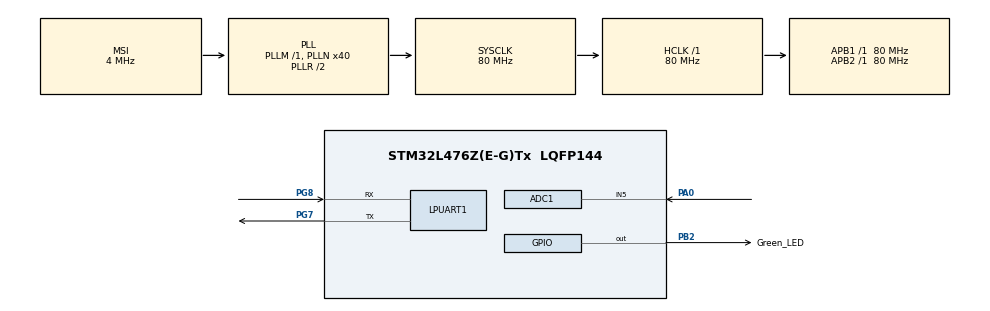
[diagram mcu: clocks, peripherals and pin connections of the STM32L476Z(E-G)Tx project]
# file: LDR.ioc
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ADC1.Channel-1\#ChannelRegularConversion=ADC_CHANNEL_5
ADC1.EnableRegularConversion=ENABLE
ADC1.NbrOfConversionFlag=1
ADC1.OffsetNumber-1\#ChannelRegularConversion=ADC_OFFSET_NONE
ADC1.Rank-1\#ChannelRegularConversion=1
ADC1.SamplingTime-1\#ChannelRegularConversion=ADC_SAMPLETIME_2CYCLES_5
ADC1.master=1
LPUART1.WordLength=UART_WORDLENGTH_8B
Mcu.Family=STM32L4
Mcu.Name=STM32L476Z(E-G)Tx
Mcu.Package=LQFP144
NVIC.PriorityGroup=NVIC_PRIORITYGROUP_4
PA0.Signal=ADCx_IN5
PA13\ (JTMS-SWDIO).Mode=Serial_Wire
PA13\ (JTMS-SWDIO).Signal=SYS_JTMS-SWDIO
PA14\ (JTCK-SWCLK).Mode=Serial_Wire
PA14\ (JTCK-SWCLK).Signal=SYS_JTCK-SWCLK
PB2.GPIO_Label=Green_LED
PB2.Signal=GPIO_Output
PG7.Mode=Asynchronous
PG7.Signal=LPUART1_TX
PG8.Mode=Asynchronous
PG8.Signal=LPUART1_RX
PH0-OSC_IN\ (PH0).Mode=HSE-External-Oscillator
PH0-OSC_IN\ (PH0).Signal=RCC_OSC_IN
PH1-OSC_OUT\ (PH1).Mode=HSE-External-Oscillator
PH1-OSC_OUT\ (PH1).Signal=RCC_OSC_OUT
ProjectManager.HeapSize=0x200
ProjectManager.StackSize=0x400
ProjectManager.TargetToolchain=STM32CubeIDE
RCC.ADCFreq_Value=32000000
RCC.AHBFreq_Value=80000000
RCC.APB1Freq_Value=80000000
RCC.APB1TimFreq_Value=80000000
RCC.APB2Freq_Value=80000000
RCC.APB2TimFreq_Value=80000000
RCC.CortexFreq_Value=80000000
RCC.HCLKFreq_Value=80000000
RCC.HSE_VALUE=8000000
RCC.HSI_VALUE=16000000
RCC.LSE_VALUE=32768
RCC.MSI_VALUE=4000000
RCC.PLLN=40
RCC.PLLSAI1N=16
RCC.SYSCLKFreq_VALUE=80000000
RCC.SYSCLKSource=RCC_SYSCLKSOURCE_PLLCLK
RCC.USBFreq_Value=32000000
RCC.VCOOutputFreq_Value=160000000
SH.ADCx_IN5.0=ADC1_IN5,IN5-Single-Ended
board=custom

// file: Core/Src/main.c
/* USER CODE BEGIN Header */
/**
  ******************************************************************************
  * @file           : main.c
  * @brief          : Main program body
  ******************************************************************************
  * @attention
  *
  * Copyright (c) 2024 STMicroelectronics.
  * All rights reserved.
  *
  * This software is licensed under terms that can be found in the LICENSE file
  * in the root directory of this software component.
  * If no LICENSE file comes with this software, it is provided AS-IS.
  *
  ******************************************************************************
  */
/* USER CODE END Header */
#include "main.h"

/* USER CODE BEGIN Includes */
#include <stdio.h>
#include <string.h>

/* USER CODE END Includes */

ADC_HandleTypeDef hadc1;

UART_HandleTypeDef hlpuart1;

void SystemClock_Config(void);
static void MX_GPIO_Init(void);
static void MX_ADC1_Init(void);
static void MX_LPUART1_UART_Init(void);

/* USER CODE BEGIN 0 */
uint16_t data;
char buffer[20];

/* USER CODE END 0 */

int main(void)
{

  /* MCU Configuration--------------------------------------------------------*/

  /* Reset of all peripherals, Initializes the Flash interface and the Systick. */
  HAL_Init();

  /* Configure the system clock */
  SystemClock_Config();

  /* Initialize all configured peripherals */
  MX_GPIO_Init();
  MX_ADC1_Init();
  MX_LPUART1_UART_Init();

  /* Infinite loop */
  /* USER CODE BEGIN WHILE */
  while (1)
  {
	  HAL_ADC_Start(&hadc1);
	  HAL_ADC_PollForConversion(&hadc1, 20);
	  data = HAL_ADC_GetValue(&hadc1);
	  sprintf(buffer, "Value: %u \r \n", data);
	  HAL_UART_Transmit(&hlpuart1, (uint8_t *) buffer, strlen(buffer), HAL_MAX_DELAY);
	  HAL_Delay(500);

	  if (data > 1000)
	  {
		  HAL_GPIO_WritePin(GPIOB, GPIO_PIN_2, GPIO_PIN_SET);
	  }else
	  {
		  HAL_GPIO_WritePin(GPIOB, GPIO_PIN_2, GPIO_PIN_RESET);
	  }
	 // HAL_Delay(200);
//
//	  if((HAL_GPIO_ReadPin(GPIOA, GPIO_PIN_0) == GPIO_PIN_RESET))
//	{
//			  HAL_GPIO_WritePin(GPIOB, GPIO_PIN_2, GPIO_PIN_SET);
//  }else
//	  HAL_GPIO_WritePin(GPIOB, GPIO_PIN_2, GPIO_PIN_RESET);

    /* USER CODE END WHILE */

  }
}

void SystemClock_Config(void)
{
  RCC_OscInitTypeDef RCC_OscInitStruct = {0};
  RCC_ClkInitTypeDef RCC_ClkInitStruct = {0};

  /** Configure the main internal regulator output voltage
  */
  if (HAL_PWREx_ControlVoltageScaling(PWR_REGULATOR_VOLTAGE_SCALE1) != HAL_OK)
  {
    Error_Handler();
  }

  /** Initializes the RCC Oscillators according to the specified parameters
  * in the RCC_OscInitTypeDef structure.
  */
  RCC_OscInitStruct.OscillatorType = RCC_OSCILLATORTYPE_MSI;
  RCC_OscInitStruct.MSIState = RCC_MSI_ON;
  RCC_OscInitStruct.MSICalibrationValue = 0;
  RCC_OscInitStruct.MSIClockRange = RCC_MSIRANGE_6;
  RCC_OscInitStruct.PLL.PLLState = RCC_PLL_ON;
  RCC_OscInitStruct.PLL.PLLSource = RCC_PLLSOURCE_MSI;
  RCC_OscInitStruct.PLL.PLLM = 1;
  RCC_OscInitStruct.PLL.PLLN = 40;
  RCC_OscInitStruct.PLL.PLLP = RCC_PLLP_DIV7;
  RCC_OscInitStruct.PLL.PLLQ = RCC_PLLQ_DIV2;
  RCC_OscInitStruct.PLL.PLLR = RCC_PLLR_DIV2;
  if (HAL_RCC_OscConfig(&RCC_OscInitStruct) != HAL_OK)
  {
    Error_Handler();
  }

  /** Initializes the CPU, AHB and APB buses clocks
  */
  RCC_ClkInitStruct.ClockType = RCC_CLOCKTYPE_HCLK|RCC_CLOCKTYPE_SYSCLK
                              |RCC_CLOCKTYPE_PCLK1|RCC_CLOCKTYPE_PCLK2;
  RCC_ClkInitStruct.SYSCLKSource = RCC_SYSCLKSOURCE_PLLCLK;
  RCC_ClkInitStruct.AHBCLKDivider = RCC_SYSCLK_DIV1;
  RCC_ClkInitStruct.APB1CLKDivider = RCC_HCLK_DIV1;
  RCC_ClkInitStruct.APB2CLKDivider = RCC_HCLK_DIV1;

  if (HAL_RCC_ClockConfig(&RCC_ClkInitStruct, FLASH_LATENCY_4) != HAL_OK)
  {
    Error_Handler();
  }
}

static void MX_ADC1_Init(void)
{

  ADC_MultiModeTypeDef multimode = {0};
  ADC_ChannelConfTypeDef sConfig = {0};

  /** Common config
  */
  hadc1.Instance = ADC1;
  hadc1.Init.ClockPrescaler = ADC_CLOCK_ASYNC_DIV1;
  hadc1.Init.Resolution = ADC_RESOLUTION_12B;
  hadc1.Init.DataAlign = ADC_DATAALIGN_RIGHT;
  hadc1.Init.ScanConvMode = ADC_SCAN_DISABLE;
  hadc1.Init.EOCSelection = ADC_EOC_SINGLE_CONV;
  hadc1.Init.LowPowerAutoWait = DISABLE;
  hadc1.Init.ContinuousConvMode = DISABLE;
  hadc1.Init.NbrOfConversion = 1;
  hadc1.Init.DiscontinuousConvMode = DISABLE;
  hadc1.Init.ExternalTrigConv = ADC_SOFTWARE_START;
  hadc1.Init.ExternalTrigConvEdge = ADC_EXTERNALTRIGCONVEDGE_NONE;
  hadc1.Init.DMAContinuousRequests = DISABLE;
  hadc1.Init.Overrun = ADC_OVR_DATA_PRESERVED;
  hadc1.Init.OversamplingMode = DISABLE;
  if (HAL_ADC_Init(&hadc1) != HAL_OK)
  {
    Error_Handler();
  }

  /** Configure the ADC multi-mode
  */
  multimode.Mode = ADC_MODE_INDEPENDENT;
  if (HAL_ADCEx_MultiModeConfigChannel(&hadc1, &multimode) != HAL_OK)
  {
    Error_Handler();
  }

  /** Configure Regular Channel
  */
  sConfig.Channel = ADC_CHANNEL_5;
  sConfig.Rank = ADC_REGULAR_RANK_1;
  sConfig.SamplingTime = ADC_SAMPLETIME_2CYCLES_5;
  sConfig.SingleDiff = ADC_SINGLE_ENDED;
  sConfig.OffsetNumber = ADC_OFFSET_NONE;
  sConfig.Offset = 0;
  if (HAL_ADC_ConfigChannel(&hadc1, &sConfig) != HAL_OK)
  {
    Error_Handler();
  }

}

static void MX_LPUART1_UART_Init(void)
{

  hlpuart1.Instance = LPUART1;
  hlpuart1.Init.BaudRate = 209700;
  hlpuart1.Init.WordLength = UART_WORDLENGTH_8B;
  hlpuart1.Init.StopBits = UART_STOPBITS_1;
  hlpuart1.Init.Parity = UART_PARITY_NONE;
  hlpuart1.Init.Mode = UART_MODE_TX_RX;
  hlpuart1.Init.HwFlowCtl = UART_HWCONTROL_NONE;
  hlpuart1.Init.OneBitSampling = UART_ONE_BIT_SAMPLE_DISABLE;
  hlpuart1.AdvancedInit.AdvFeatureInit = UART_ADVFEATURE_NO_INIT;
  if (HAL_UART_Init(&hlpuart1) != HAL_OK)
  {
    Error_Handler();
  }

}

static void MX_GPIO_Init(void)
{
  GPIO_InitTypeDef GPIO_InitStruct = {0};

  /* GPIO Ports Clock Enable */
  __HAL_RCC_GPIOH_CLK_ENABLE();
  __HAL_RCC_GPIOA_CLK_ENABLE();
  __HAL_RCC_GPIOB_CLK_ENABLE();
  __HAL_RCC_GPIOG_CLK_ENABLE();
  HAL_PWREx_EnableVddIO2();

  /*Configure GPIO pin Output Level */
  HAL_GPIO_WritePin(Green_LED_GPIO_Port, Green_LED_Pin, GPIO_PIN_RESET);

  /*Configure GPIO pin : Green_LED_Pin */
  GPIO_InitStruct.Pin = Green_LED_Pin;
  GPIO_InitStruct.Mode = GPIO_MODE_OUTPUT_PP;
  GPIO_InitStruct.Pull = GPIO_NOPULL;
  GPIO_InitStruct.Speed = GPIO_SPEED_FREQ_LOW;
  HAL_GPIO_Init(Green_LED_GPIO_Port, &GPIO_InitStruct);

}

void Error_Handler(void)
{
  __disable_irq();
  while (1)
  {
  }
}
